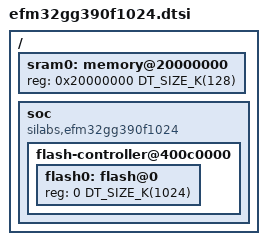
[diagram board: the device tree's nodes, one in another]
/*
 * Copyright (c) 2018 Christian Taedcke
 *
 * SPDX-License-Identifier: Apache-2.0
 */

#include <mem.h>
#include <silabs/efm32gg.dtsi>

/ {
	sram0: memory@20000000 {
		reg = <0x20000000 DT_SIZE_K(128)>;
	};

	soc {
		compatible = "silabs,efm32gg390f1024", "silabs,efm32gg", "silabs,efm32", "simple-bus";

		flash-controller@400c0000 {
			flash0: flash@0 {
				reg = <0 DT_SIZE_K(1024)>;
			};
		};
	};
};
